# PY32T020xx register map
Vendor: Puya; Series: PY32L0; File version: 1.0.0
Arm 32-bit Cortex-M0+ Microcontroller based device, CPU clock up to 48 MHz.
CPU: CM0+ r0p1, little endian, no MPU, no FPU, 4 interrupt priority bits
Registers are 32-bit, read-write, reset 0x0 unless marked. A register's access mark holds for its fields unless they carry their own. Offsets are from the block's base; lines under a group give offsets from that group; [hi:lo] are bit positions; {n}, {i} and the like mark numbered series; 'fields as' and 'values as' point back to an identical list; <NAME> marks a mode.

## Memory map
0x40002000 TIM14 size 0x400 — General purpose timer
0x40002800 RTC size 0x400 — Real time clock
0x40003000 IWDG size 0x400 — Independent watchdog
0x40003800 TK size 0x400 — Touch key
0x40004400 UART1 size 0x400 — Universal asynchronous receiver transmitter
0x40005400 I2C size 0x400 — Inter integrated circuit
0x40007000 PWR size 0x400 — Power control
0x40007C00 LPTIM1 size 0x400 — Low power timer
0x40010000 SYSCFG size 0x100 — System configuration controller
0x40010200 COMP1 size 0x10 — Comparator 1
0x40010210 COMP2 size 0x10 — Comparator2
0x40012400 ADC size 0x400 — Analog to Digital Converter
0x40012C00 TIM1 size 0x400 — Advanced timer
0x40013000 SPI1 size 0x400 — Serial peripheral interface
0x40013800 UART3 size 0x400
0x40014400 UART2 size 0x400
0x40015800 DBGMCU size 0x400 — Debug support
0x40021000 RCC size 0x400 — Reset and clock control
0x40021800 EXTI size 0x400 — External interrupt/event controller
0x40022000 FLASH size 0x400
0x40023000 CRC size 0x400 — CRC calculation unit
0x50000000 GPIOA size 0x400 — General-purpose I/Os
0x50000400 GPIOB size 0x400 — General-purpose I/Os
0x50001400 GPIOF size 0x400

## Interrupts
2 RTC — RTC Interrupt through EXTI Lines 19
3 FLASH — FLASH global Interrupt
4 RCC — RCC global Interrupt
5 EXTI0_1 (EXTI) — EXTI Line 0 and 1 Interrupt
6 EXTI2_3 (EXTI) — EXTI Line 2 and 3 Interrupt
7 EXTI4_15 (EXTI) — EXTI Line 4 to 15 Interrupt
12 ADC_COMP (ADC, COMP1, COMP2) — ADC and COMP Interrupts
13 TIM1_BRK_UP_TRG_COM (TIM1) — TIM1 Break, Update, Trigger and Commutation Interrupt
14 TIM1_CC (TIM1) — TIM1 Capture Compare Interrupt
17 LPTIM1_DAC (LPTIM1) — LPTIM1, DAC global Interrupts
19 TIM14 — TIM14 global Interrupt
23 I2C1 (I2C) — I2C1 global Interrupt
25 SPI1 — SPI1 global Interrupt
29 UART3 — UART3 global Interrupt
30 UART2 — UART2 global Interrupt
31 UART1 — UART1 global Interrupt

## ADC — Analog to Digital Converter
Base 0x40012400
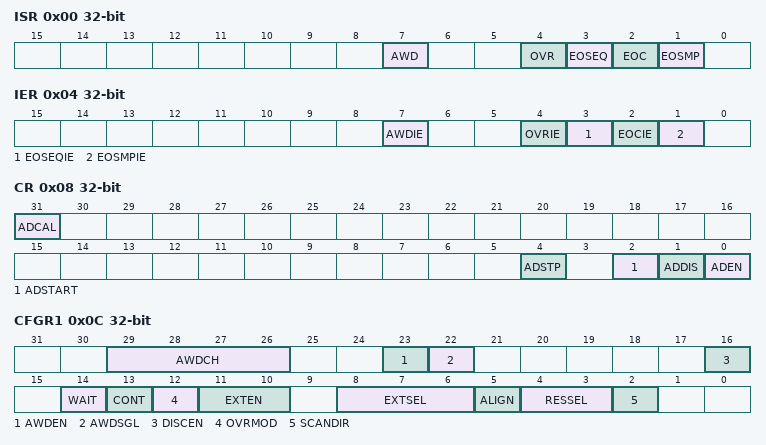
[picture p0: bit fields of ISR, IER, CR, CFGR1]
0x00 ISR — ADC interrupt and status register
  [7] AWD — ADC analog watchdog flag
  [4] OVR — ADC group regular overrun flag
  [3] EOSEQ — ADC group regular end of sequence conversions flag
  [2] EOC — ADC group regular end of unitary conversion flag
  [1] EOSMP — ADC group regular end of sampling flag
0x04 IER — ADC interrupt enable register
  [7] AWDIE — ADC analog watchdog interrupt
  [4] OVRIE — ADC group regular overrun interrupt
  [3] EOSEQIE — ADC group regular end of sequence conversions interrupt
  [2] EOCIE — ADC group regular end of unitary conversion interrupt
  [1] EOSMPIE — ADC group regular end of sampling interrupt
0x08 CR — ADC control register
  [31] ADCAL — calibration enable
  [4] ADSTP — stop conversion
  [2] ADSTART — start conversion
  [1] ADDIS — addis conversion
  [0] ADEN — enabl adc
0x0C CFGR1 — ADC configuration register 1
  [29:26] AWDCH — awd channels
    1=0; 2=1; 4=2; 8=3
  [23] AWDEN — awd enable
  [22] AWDSGL — awd single mode
  [16] DISCEN — discent mode
  [14] WAIT — wait mode
  [13] CONT — continul mode
  [12] OVRMOD — over mode
  [11:10] EXTEN — trigle mode select
    1=0; 2=1
  [8:6] EXTSEL — tigle select
    1=0; 2=1; 4=2
  [5] ALIGN — align mode
  [4:3] RESSEL ro — conversion ressel select
    1=0; 2=1
  [2] SCANDIR — sequence direction
0x14 SMP
  [2:0] SMP — sample time
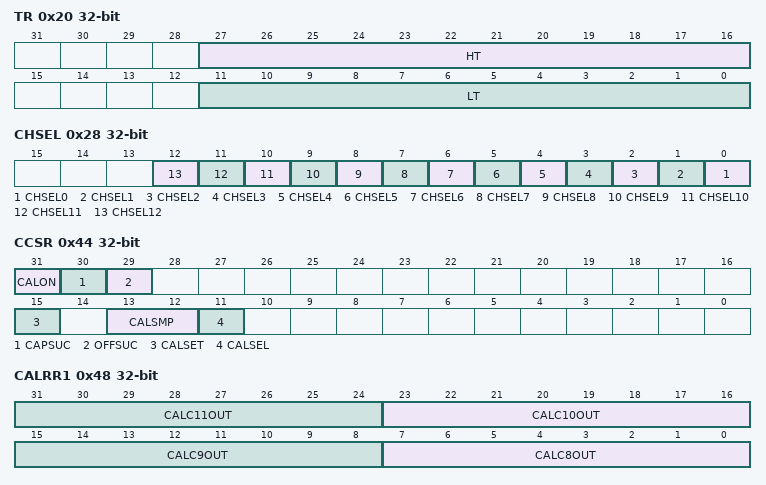
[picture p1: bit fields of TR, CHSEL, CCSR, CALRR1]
0x20 TR — ADC analog watchdog 1 threshold register
  [27:16] HT — watch dog values of high
    1=0; 2=1; 4=2; 8=3; 16=4; 32=5; 64=6; 128=7; 0x100=8; 0x200=9; 0x400=10; 0x800=11
  [11:0] LT — watch dog values of low
    values as HT
0x28 CHSEL
  [n] CHSEL{n} (n=0..12) — Channel-{n} selection
0x40 DR — ADC group regular data register
  [15:0] DATA ro — conversion data
    1=0; 2=1; 4=2; 8=3; 16=4; 32=5; 64=6; 128=7; 0x100=8; 0x200=9; 0x400=10; 0x800=11; 0x1000=12; 0x2000=13; 0x4000=14; 0x8000=15
0x44 CCSR — ADC calibration configuration and status register
  [31] CALON ro — calibration status
  [30] CAPSUC — capu calibration success
  [29] OFFSUC — offset line calibration success
  [15] CALSET — calibration value of set
  [13:12] CALSMP — calibration sample time
    1=0; 2=1
  [11] CALSEL — calibration mode select
0x48 CALRR1 — ADC calibration result register 1
  [8n-57:8n-64] CALC{n}OUT ro (n=8..11)
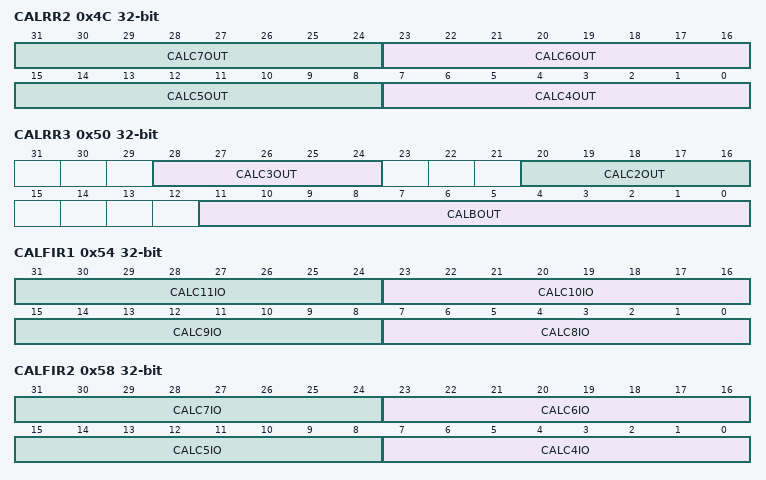
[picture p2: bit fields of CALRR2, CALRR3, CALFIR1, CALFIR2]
0x4C CALRR2 — ADC calibration result register 2
  [8n-25:8n-32] CALC{n}OUT ro (n=4..7)
0x50 CALRR3 — ADC calibration result register 3
  [28:24] CALC3OUT ro, [20:16] CALC2OUT ro, [11:0] CALBOUT ro
0x54 CALFIR1 — ADC calibration factor input register 1
  [8n-57:8n-64] CALC{n}IO (n=8..11)
0x58 CALFIR2 — ADC calibration factor input register 2
  [8n-25:8n-32] CALC{n}IO (n=4..7)
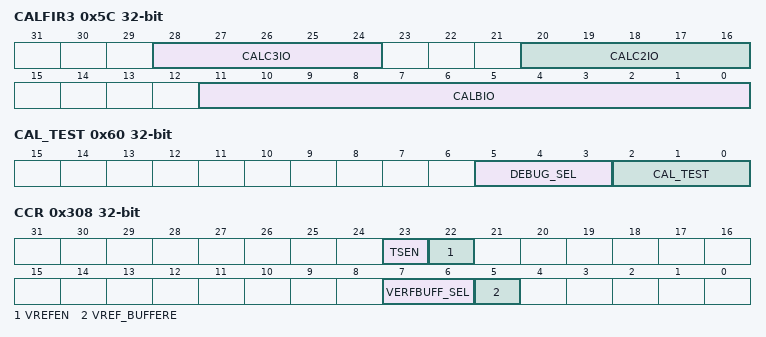
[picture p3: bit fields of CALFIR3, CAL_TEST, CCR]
0x5C CALFIR3 — ADC calibration factor input register 2
  [28:24] CALC3IO, [20:16] CALC2IO, [11:0] CALBIO
0x60 CAL_TEST
  [5:3] DEBUG_SEL — debug mode select output of sigs
  [2:0] CAL_TEST — calibration test values
0x308 CCR — ADC common configuration register
  [23] TSEN — ts line enable
  [22] VREFEN — reference voltage enable
  [7:6] VERFBUFF_SEL — VREFBUF output voltage select
  [5] VREF_BUFFERE — VerfBuffer enable
